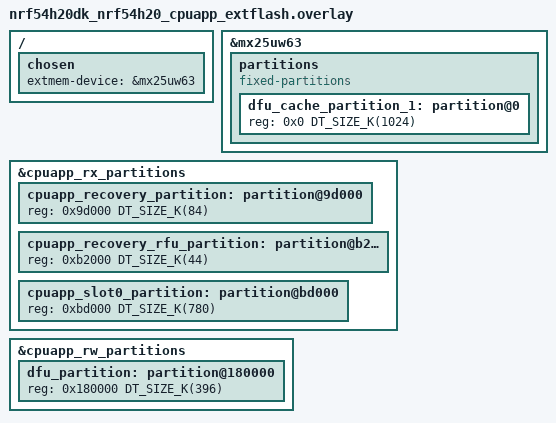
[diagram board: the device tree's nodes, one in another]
/*
 * Copyright (c) 2024 Nordic Semiconductor ASA
 *
 * SPDX-License-Identifier: LicenseRef-Nordic-5-Clause
 */

/ {
	chosen {
		extmem-device = &mx25uw63;
	};
};

&mx25uw63 {
	status = "okay";
	partitions {
		compatible = "fixed-partitions";
		#address-cells = <1>;
		#size-cells = <1>;

		dfu_cache_partition_1: partition@0 {
			reg = <0x0 DT_SIZE_K(1024)>;
		};
	};
};

&cpuapp_rx_partitions {
	/delete-node/ partition@9d000;
	cpuapp_recovery_partition: partition@9d000 {
		reg = <0x9d000 DT_SIZE_K(84)>;
	};

	/delete-node/ partition@af000;
	cpuapp_recovery_rfu_partition: partition@b2000 {
		reg = <0xb2000 DT_SIZE_K(44)>;
	};

	/delete-node/ partition@bd000;
	cpuapp_slot0_partition: partition@bd000 {
		reg = <0xbd000 DT_SIZE_K(780)>;
	};
};

&cpuapp_rw_partitions {
	/delete-node/ partition@100000;
	dfu_partition: partition@180000 {
		reg = < 0x180000 DT_SIZE_K(396) >;
	};
};
